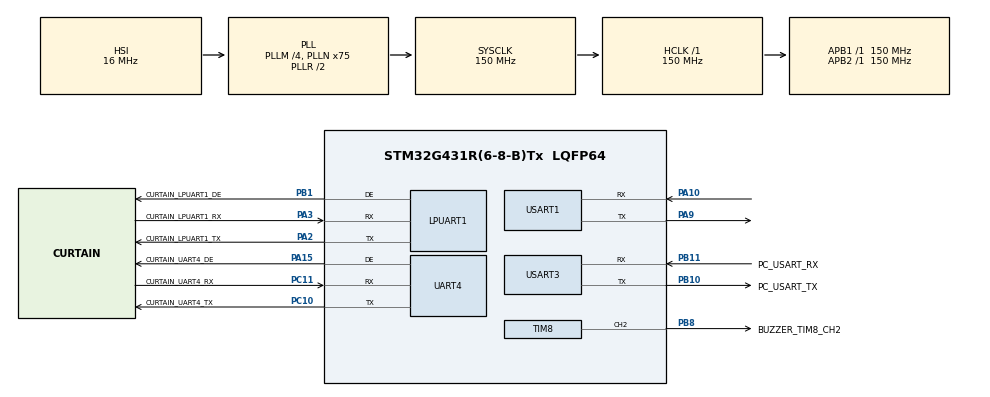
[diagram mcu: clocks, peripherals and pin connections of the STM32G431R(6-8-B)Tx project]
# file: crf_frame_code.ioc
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Mcu.Family=STM32G4
Mcu.Name=STM32G431R(6-8-B)Tx
Mcu.Package=LQFP64
NVIC.FLASH_IRQn=true\:0\:0\:false\:false\:true\:true\:true\:true
NVIC.FPU_IRQn=true\:0\:0\:false\:false\:true\:true\:false\:true
NVIC.LPUART1_IRQn=true\:0\:0\:false\:false\:true\:true\:true\:true
NVIC.PVD_PVM_IRQn=true\:0\:0\:false\:false\:true\:true\:true\:true
NVIC.PriorityGroup=NVIC_PRIORITYGROUP_4
NVIC.RCC_IRQn=true\:0\:0\:false\:false\:true\:true\:false\:true
NVIC.TIM8_BRK_IRQn=true\:0\:0\:false\:false\:true\:true\:true\:true
NVIC.TIM8_CC_IRQn=true\:0\:0\:false\:false\:true\:true\:true\:true
NVIC.TIM8_TRG_COM_IRQn=true\:0\:0\:false\:false\:true\:true\:true\:true
NVIC.TIM8_UP_IRQn=true\:0\:0\:false\:false\:true\:true\:true\:true
NVIC.UART4_IRQn=true\:0\:0\:false\:false\:true\:true\:true\:true
NVIC.USART1_IRQn=true\:0\:0\:false\:false\:true\:true\:true\:true
NVIC.USART3_IRQn=true\:0\:0\:false\:false\:true\:true\:true\:true
PA10.Mode=Asynchronous
PA10.Signal=USART1_RX
PA13.Mode=Serial_Wire
PA13.Signal=SYS_JTMS-SWDIO
PA14.Mode=Serial_Wire
PA14.Signal=SYS_JTCK-SWCLK
PA15.GPIO_Label=CURTAIN_UART4_DE
PA15.Mode=Hardware Flow Control (RS485)
PA15.Signal=UART4_DE
PA2.GPIO_Label=CURTAIN_LPUART1_TX
PA2.Mode=Asynchronous
PA2.Signal=LPUART1_TX
PA3.GPIO_Label=CURTAIN_LPUART1_RX
PA3.Mode=Asynchronous
PA3.Signal=LPUART1_RX
PA9.Mode=Asynchronous
PA9.Signal=USART1_TX
PB1.GPIO_Label=CURTAIN_LPUART1_DE
PB1.Mode=Hardware Flow Control (RS485)
PB1.Signal=LPUART1_DE
PB10.GPIO_Label=PC_USART_TX
PB10.Mode=Asynchronous
PB10.Signal=USART3_TX
PB11.GPIO_Label=PC_USART_RX
PB11.Mode=Asynchronous
PB11.Signal=USART3_RX
PB8-BOOT0.GPIO_Label=BUZZER_TIM8_CH2
PB8-BOOT0.Signal=S_TIM8_CH2
PC10.GPIO_Label=CURTAIN_UART4_TX
PC10.Mode=Asynchronous
PC10.Signal=UART4_TX
PC11.GPIO_Label=CURTAIN_UART4_RX
PC11.Mode=Asynchronous
PC11.Signal=UART4_RX
PF0-OSC_IN.Mode=HSE-External-Clock-Source
PF0-OSC_IN.Signal=RCC_OSC_IN
ProjectManager.HeapSize=0x200
ProjectManager.StackSize=0x400
ProjectManager.TargetToolchain=MDK-ARM V5.32
RCC.ADC12Freq_Value=150000000
RCC.AHBFreq_Value=150000000
RCC.APB1Freq_Value=150000000
RCC.APB1TimFreq_Value=150000000
RCC.APB2Freq_Value=150000000
RCC.APB2TimFreq_Value=150000000
RCC.CortexFreq_Value=150000000
RCC.EXTERNAL_CLOCK_VALUE=12288000
RCC.HCLKFreq_Value=150000000
RCC.HSE_VALUE=8000000
RCC.HSI48_VALUE=48000000
RCC.HSI_VALUE=16000000
RCC.LSE_VALUE=32768
RCC.PLLM=RCC_PLLM_DIV4
RCC.PLLN=75
RCC.SYSCLKFreq_VALUE=150000000
RCC.SYSCLKSource=RCC_SYSCLKSOURCE_PLLCLK
RCC.USBFreq_Value=150000000
RCC.VCOOutputFreq_Value=300000000
SH.S_TIM8_CH2.0=TIM8_CH2,PWM Generation2 CH2
TIM8.Channel-PWM\ Generation2\ CH2=TIM_CHANNEL_2
TIM8.PeriodNoDither=1000-1
TIM8.Prescaler=150-1
TIM8.PulseNoDither_2=500
USART1.VirtualMode-Asynchronous=VM_ASYNC
USART3.VirtualMode-Asynchronous=VM_ASYNC
VP_SYS_VS_DBSignals.Mode=DisableDeadBatterySignals
VP_TIM8_VS_ClockSourceINT.Mode=Internal
board=custom

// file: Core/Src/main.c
/* USER CODE BEGIN Header */
/**
  ******************************************************************************
  * @file           : main.c
  * @brief          : Main program body
  ******************************************************************************
  * @attention
  *
  * Copyright (c) 2025 STMicroelectronics.
  * All rights reserved.
  *
  * This software is licensed under terms that can be found in the LICENSE file
  * in the root directory of this software component.
  * If no LICENSE file comes with this software, it is provided AS-IS.
  *
  ******************************************************************************
  */
/* USER CODE END Header */
#include "main.h"
#include "usart.h"
#include "tim.h"
#include "gpio.h"

/* USER CODE BEGIN Includes */
#include "unit_common.h"
/* USER CODE END Includes */

void SystemClock_Config(void);

int main(void)
{

  /* MCU Configuration--------------------------------------------------------*/

  /* Reset of all peripherals, Initializes the Flash interface and the Systick. */
  HAL_Init();

  /* Configure the system clock */
  SystemClock_Config();

  /* Initialize all configured peripherals */
  MX_GPIO_Init();
  MX_USART3_UART_Init();
  MX_LPUART1_UART_Init();
  MX_UART4_Init();
  MX_USART1_UART_Init();
  MX_TIM8_Init();
  /* USER CODE BEGIN 2 */
  printf("Hello World!\r\n");
  // //只需开启PWM输出功能，即可让蜂鸣器响
  // HAL_TIM_PWM_Start(&htim8,TIM_CHANNEL_2);
  // int duty = 50;
  unit_test_main();
  /* USER CODE END 2 */

  /* Infinite loop */
  /* USER CODE BEGIN WHILE */
  while (1)
  {
    // /* USER CODE END WHILE */
    // // 示例：设置TIM8通道2的占空比为50%
    // PWM_SetDuty(&htim8, TIM_CHANNEL_2, duty);
    // duty -= 10;
    // if (duty < 0) {
    //     duty = 70;
    // }
    // HAL_Delay(2000);

    // //关闭PWM输出，即关闭蜂鸣器
    // HAL_TIM_PWM_Stop(&htim8,TIM_CHANNEL_2);
    // HAL_Delay(2000);

  }
}

void SystemClock_Config(void)
{
  RCC_OscInitTypeDef RCC_OscInitStruct = {0};
  RCC_ClkInitTypeDef RCC_ClkInitStruct = {0};

  /** Configure the main internal regulator output voltage
  */
  HAL_PWREx_ControlVoltageScaling(PWR_REGULATOR_VOLTAGE_SCALE1);

  /** Initializes the RCC Oscillators according to the specified parameters
  * in the RCC_OscInitTypeDef structure.
  */
  RCC_OscInitStruct.OscillatorType = RCC_OSCILLATORTYPE_HSI;
  RCC_OscInitStruct.HSIState = RCC_HSI_ON;
  RCC_OscInitStruct.HSICalibrationValue = RCC_HSICALIBRATION_DEFAULT;
  RCC_OscInitStruct.PLL.PLLState = RCC_PLL_ON;
  RCC_OscInitStruct.PLL.PLLSource = RCC_PLLSOURCE_HSI;
  RCC_OscInitStruct.PLL.PLLM = RCC_PLLM_DIV4;
  RCC_OscInitStruct.PLL.PLLN = 75;
  RCC_OscInitStruct.PLL.PLLP = RCC_PLLP_DIV2;
  RCC_OscInitStruct.PLL.PLLQ = RCC_PLLQ_DIV2;
  RCC_OscInitStruct.PLL.PLLR = RCC_PLLR_DIV2;
  if (HAL_RCC_OscConfig(&RCC_OscInitStruct) != HAL_OK)
  {
    Error_Handler();
  }

  /** Initializes the CPU, AHB and APB buses clocks
  */
  RCC_ClkInitStruct.ClockType = RCC_CLOCKTYPE_HCLK|RCC_CLOCKTYPE_SYSCLK
                              |RCC_CLOCKTYPE_PCLK1|RCC_CLOCKTYPE_PCLK2;
  RCC_ClkInitStruct.SYSCLKSource = RCC_SYSCLKSOURCE_PLLCLK;
  RCC_ClkInitStruct.AHBCLKDivider = RCC_SYSCLK_DIV1;
  RCC_ClkInitStruct.APB1CLKDivider = RCC_HCLK_DIV1;
  RCC_ClkInitStruct.APB2CLKDivider = RCC_HCLK_DIV1;

  if (HAL_RCC_ClockConfig(&RCC_ClkInitStruct, FLASH_LATENCY_4) != HAL_OK)
  {
    Error_Handler();
  }
}

void Error_Handler(void)
{
  __disable_irq();
  while (1)
  {
  }
}
